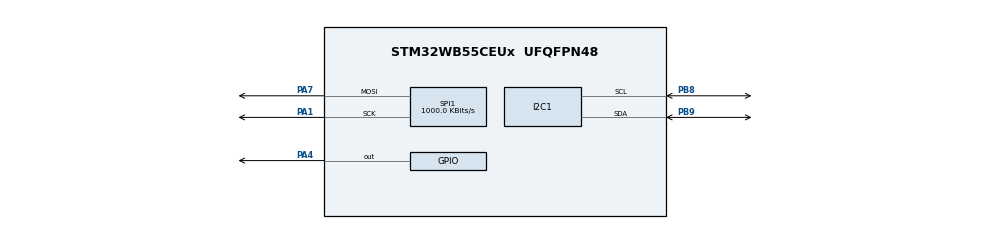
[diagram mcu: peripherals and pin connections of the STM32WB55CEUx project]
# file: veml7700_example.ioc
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Mcu.Family=STM32WB
Mcu.Name=STM32WB55CEUx
Mcu.Package=UFQFPN48
NVIC.PriorityGroup=NVIC_PRIORITYGROUP_4
PA1.Mode=TX_Only_Simplex_Unidirect_Master
PA1.Signal=SPI1_SCK
PA4.PinState=GPIO_PIN_SET
PA4.Signal=GPIO_Output
PA7.Mode=TX_Only_Simplex_Unidirect_Master
PA7.Signal=SPI1_MOSI
PB8.Mode=I2C
PB8.Signal=I2C1_SCL
PB9.Mode=I2C
PB9.Signal=I2C1_SDA
ProjectManager.HeapSize=0x200
ProjectManager.StackSize=0x400
ProjectManager.TargetToolchain=STM32CubeIDE
RCC.APB3Freq_Value=16000000
RCC.HSE_VALUE=8000000
RCC.HSI48_VALUE=48000000
RCC.HSI_VALUE=16000000
RCC.LSE_VALUE=32768
RCC.VCOOutputFreq_Value=32000000
SPI1.BaudRatePrescaler=SPI_BAUDRATEPRESCALER_4
SPI1.CalculateBaudRate=1000.0 KBits/s
SPI1.DataSize=SPI_DATASIZE_8BIT
SPI1.Direction=SPI_DIRECTION_2LINES
SPI1.Mode=SPI_MODE_MASTER
SPI1.NSSPMode=SPI_NSS_PULSE_DISABLE
SPI1.VirtualType=VM_MASTER
board=custom

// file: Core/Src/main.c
/* USER CODE BEGIN Header */
/**
  ******************************************************************************
  * @file           : main.c
  * @brief          : Main program body
  ******************************************************************************
  * @attention
  *
  * <h2><center>&copy; Copyright (c) 2021 STMicroelectronics.
  * All rights reserved.</center></h2>
  *
  * This software component is licensed by ST under BSD 3-Clause license,
  * the "License"; You may not use this file except in compliance with the
  * License. You may obtain a copy of the License at:
  *                        opensource.org/licenses/BSD-3-Clause
  *
  ******************************************************************************
  */
/* USER CODE END Header */
#include "main.h"

/* USER CODE BEGIN Includes */
#include "dotstar.h"
#include "veml7700.h"
#include "er_oled.h"
#define NUM_PIXELS 12
#define OLED_RESET_Pin GPIO_PIN_0
#define OLED_RESET_GPIO_Port GPIOB

/* USER CODE END Includes */

I2C_HandleTypeDef hi2c1;

SPI_HandleTypeDef hspi1;

void SystemClock_Config(void);
static void MX_GPIO_Init(void);
static void MX_SPI1_Init(void);
static void MX_I2C1_Init(void);

int main(void)
{

  /* MCU Configuration--------------------------------------------------------*/

  /* Reset of all peripherals, Initializes the Flash interface and the Systick. */
  HAL_Init();

  /* Configure the system clock */
  SystemClock_Config();

  /* Initialize all configured peripherals */
  MX_GPIO_Init();
  MX_SPI1_Init();
  MX_I2C1_Init();
  /* USER CODE BEGIN 2 */
  DotStar_InitHandle dotstar;
  dotstar.spiHandle = &hspi1;
  dotstar.numLEDs = NUM_PIXELS;
  dotstar.colorOrder = DOTSTAR_BGR;
  Dotstar_Init(&dotstar);

  ds_clear();  //turn off
  ds_show();

  ds_setBrightness(40);
  HAL_Delay(3000);

  int head = 0;
  uint32_t color = 0xFF0000;

  uint8_t oled_buf[WIDTH * HEIGHT / 8];

  er_oled_begin();
  er_oled_clear(oled_buf);
  er_oled_string(6, 14, "  DRAMSAY", 12, 1, oled_buf);
  er_oled_display(oled_buf);
  HAL_Delay(3000);

  	veml_Setup(hi2c1, VEML_100MS_POLLING);
  	float lux;
  	float whitelux;
  	char printstring[128];
  	/* USER CODE END 2 */

  /* Infinite loop */
  while (1)
  {
	  lux = veml_Get_Lux();
	  whitelux = veml_Get_White_Lux();

	  er_oled_clear(oled_buf);
	  sprintf(printstring, "  lux:%.1f", lux);
	  er_oled_string(6, 14, printstring, 12, 1, oled_buf);
	  sprintf(printstring, "white:%.1f", whitelux);
	  er_oled_string(6, 28, printstring, 12, 1, oled_buf);
	  er_oled_display(oled_buf);

	  ds_setPixelColor32B(head, color); // 'On' pixel at head
	  ds_show();                        // Refresh strip

	  if(++head >= NUM_PIXELS) {         // Increment head index.  Off end of strip?
	     head = 0;                       //  Yes, reset head index to start
	     if((color >>= 8) == 0)          //  Next color (R->G->B) ... past blue now?
	       color = 0xFF0000;             //   Yes, reset to red
	  }

	  HAL_Delay(80);

  }
}

void SystemClock_Config(void)
{
  RCC_OscInitTypeDef RCC_OscInitStruct = {0};
  RCC_ClkInitTypeDef RCC_ClkInitStruct = {0};
  RCC_PeriphCLKInitTypeDef PeriphClkInitStruct = {0};

  /** Configure the main internal regulator output voltage
  */
  __HAL_PWR_VOLTAGESCALING_CONFIG(PWR_REGULATOR_VOLTAGE_SCALE1);
  /** Initializes the RCC Oscillators according to the specified parameters
  * in the RCC_OscInitTypeDef structure.
  */
  RCC_OscInitStruct.OscillatorType = RCC_OSCILLATORTYPE_HSI|RCC_OSCILLATORTYPE_MSI;
  RCC_OscInitStruct.HSIState = RCC_HSI_ON;
  RCC_OscInitStruct.MSIState = RCC_MSI_ON;
  RCC_OscInitStruct.HSICalibrationValue = RCC_HSICALIBRATION_DEFAULT;
  RCC_OscInitStruct.MSICalibrationValue = RCC_MSICALIBRATION_DEFAULT;
  RCC_OscInitStruct.MSIClockRange = RCC_MSIRANGE_6;
  RCC_OscInitStruct.PLL.PLLState = RCC_PLL_NONE;
  if (HAL_RCC_OscConfig(&RCC_OscInitStruct) != HAL_OK)
  {
    Error_Handler();
  }
  /** Configure the SYSCLKSource, HCLK, PCLK1 and PCLK2 clocks dividers
  */
  RCC_ClkInitStruct.ClockType = RCC_CLOCKTYPE_HCLK4|RCC_CLOCKTYPE_HCLK2
                              |RCC_CLOCKTYPE_HCLK|RCC_CLOCKTYPE_SYSCLK
                              |RCC_CLOCKTYPE_PCLK1|RCC_CLOCKTYPE_PCLK2;
  RCC_ClkInitStruct.SYSCLKSource = RCC_SYSCLKSOURCE_MSI;
  RCC_ClkInitStruct.AHBCLKDivider = RCC_SYSCLK_DIV1;
  RCC_ClkInitStruct.APB1CLKDivider = RCC_HCLK_DIV1;
  RCC_ClkInitStruct.APB2CLKDivider = RCC_HCLK_DIV1;
  RCC_ClkInitStruct.AHBCLK2Divider = RCC_SYSCLK_DIV1;
  RCC_ClkInitStruct.AHBCLK4Divider = RCC_SYSCLK_DIV1;

  if (HAL_RCC_ClockConfig(&RCC_ClkInitStruct, FLASH_LATENCY_0) != HAL_OK)
  {
    Error_Handler();
  }
  /** Initializes the peripherals clocks
  */
  PeriphClkInitStruct.PeriphClockSelection = RCC_PERIPHCLK_SMPS|RCC_PERIPHCLK_I2C1;
  PeriphClkInitStruct.I2c1ClockSelection = RCC_I2C1CLKSOURCE_PCLK1;
  PeriphClkInitStruct.SmpsClockSelection = RCC_SMPSCLKSOURCE_HSI;
  PeriphClkInitStruct.SmpsDivSelection = RCC_SMPSCLKDIV_RANGE1;
  if (HAL_RCCEx_PeriphCLKConfig(&PeriphClkInitStruct) != HAL_OK)
  {
    Error_Handler();
  }
}

static void MX_I2C1_Init(void)
{

  hi2c1.Instance = I2C1;
  hi2c1.Init.Timing = 0x00300F38;
  hi2c1.Init.OwnAddress1 = 0;
  hi2c1.Init.AddressingMode = I2C_ADDRESSINGMODE_7BIT;
  hi2c1.Init.DualAddressMode = I2C_DUALADDRESS_DISABLE;
  hi2c1.Init.OwnAddress2 = 0;
  hi2c1.Init.OwnAddress2Masks = I2C_OA2_NOMASK;
  hi2c1.Init.GeneralCallMode = I2C_GENERALCALL_DISABLE;
  hi2c1.Init.NoStretchMode = I2C_NOSTRETCH_DISABLE;
  if (HAL_I2C_Init(&hi2c1) != HAL_OK)
  {
    Error_Handler();
  }
  /** Configure Analogue filter
  */
  if (HAL_I2CEx_ConfigAnalogFilter(&hi2c1, I2C_ANALOGFILTER_ENABLE) != HAL_OK)
  {
    Error_Handler();
  }
  /** Configure Digital filter
  */
  if (HAL_I2CEx_ConfigDigitalFilter(&hi2c1, 0) != HAL_OK)
  {
    Error_Handler();
  }

}

static void MX_SPI1_Init(void)
{

  /* SPI1 parameter configuration*/
  hspi1.Instance = SPI1;
  hspi1.Init.Mode = SPI_MODE_MASTER;
  hspi1.Init.Direction = SPI_DIRECTION_2LINES;
  hspi1.Init.DataSize = SPI_DATASIZE_8BIT;
  hspi1.Init.CLKPolarity = SPI_POLARITY_LOW;
  hspi1.Init.CLKPhase = SPI_PHASE_1EDGE;
  hspi1.Init.NSS = SPI_NSS_SOFT;
  hspi1.Init.BaudRatePrescaler = SPI_BAUDRATEPRESCALER_4;
  hspi1.Init.FirstBit = SPI_FIRSTBIT_MSB;
  hspi1.Init.TIMode = SPI_TIMODE_DISABLE;
  hspi1.Init.CRCCalculation = SPI_CRCCALCULATION_DISABLE;
  hspi1.Init.CRCPolynomial = 7;
  hspi1.Init.CRCLength = SPI_CRC_LENGTH_DATASIZE;
  hspi1.Init.NSSPMode = SPI_NSS_PULSE_DISABLE;
  if (HAL_SPI_Init(&hspi1) != HAL_OK)
  {
    Error_Handler();
  }

}

static void MX_GPIO_Init(void)
{
  GPIO_InitTypeDef GPIO_InitStruct = {0};

  /* GPIO Ports Clock Enable */
  __HAL_RCC_GPIOB_CLK_ENABLE();
  __HAL_RCC_GPIOA_CLK_ENABLE();

  /*Configure GPIO pin Output Level */
  HAL_GPIO_WritePin(GPIOA, GPIO_PIN_4, GPIO_PIN_SET);

  /*Configure GPIO pin : PA4 */
  GPIO_InitStruct.Pin = GPIO_PIN_4;
  GPIO_InitStruct.Mode = GPIO_MODE_OUTPUT_PP;
  GPIO_InitStruct.Pull = GPIO_NOPULL;
  GPIO_InitStruct.Speed = GPIO_SPEED_FREQ_LOW;
  HAL_GPIO_Init(GPIOA, &GPIO_InitStruct);

  HAL_GPIO_WritePin(OLED_RESET_GPIO_Port, OLED_RESET_Pin, GPIO_PIN_RESET);

    /*Configure GPIO pin : OLED_RESET_Pin */
    GPIO_InitStruct.Pin = OLED_RESET_Pin;
    GPIO_InitStruct.Mode = GPIO_MODE_OUTPUT_PP;
    GPIO_InitStruct.Pull = GPIO_NOPULL;
    GPIO_InitStruct.Speed = GPIO_SPEED_FREQ_LOW;
    HAL_GPIO_Init(OLED_RESET_GPIO_Port, &GPIO_InitStruct);

    HAL_GPIO_WritePin(OLED_RESET_GPIO_Port, OLED_RESET_Pin, GPIO_PIN_SET);

}

void Error_Handler(void)
{
  __disable_irq();
  while (1)
  {
  }
}

/************************ (C) COPYRIGHT STMicroelectronics *****END OF FILE****/
